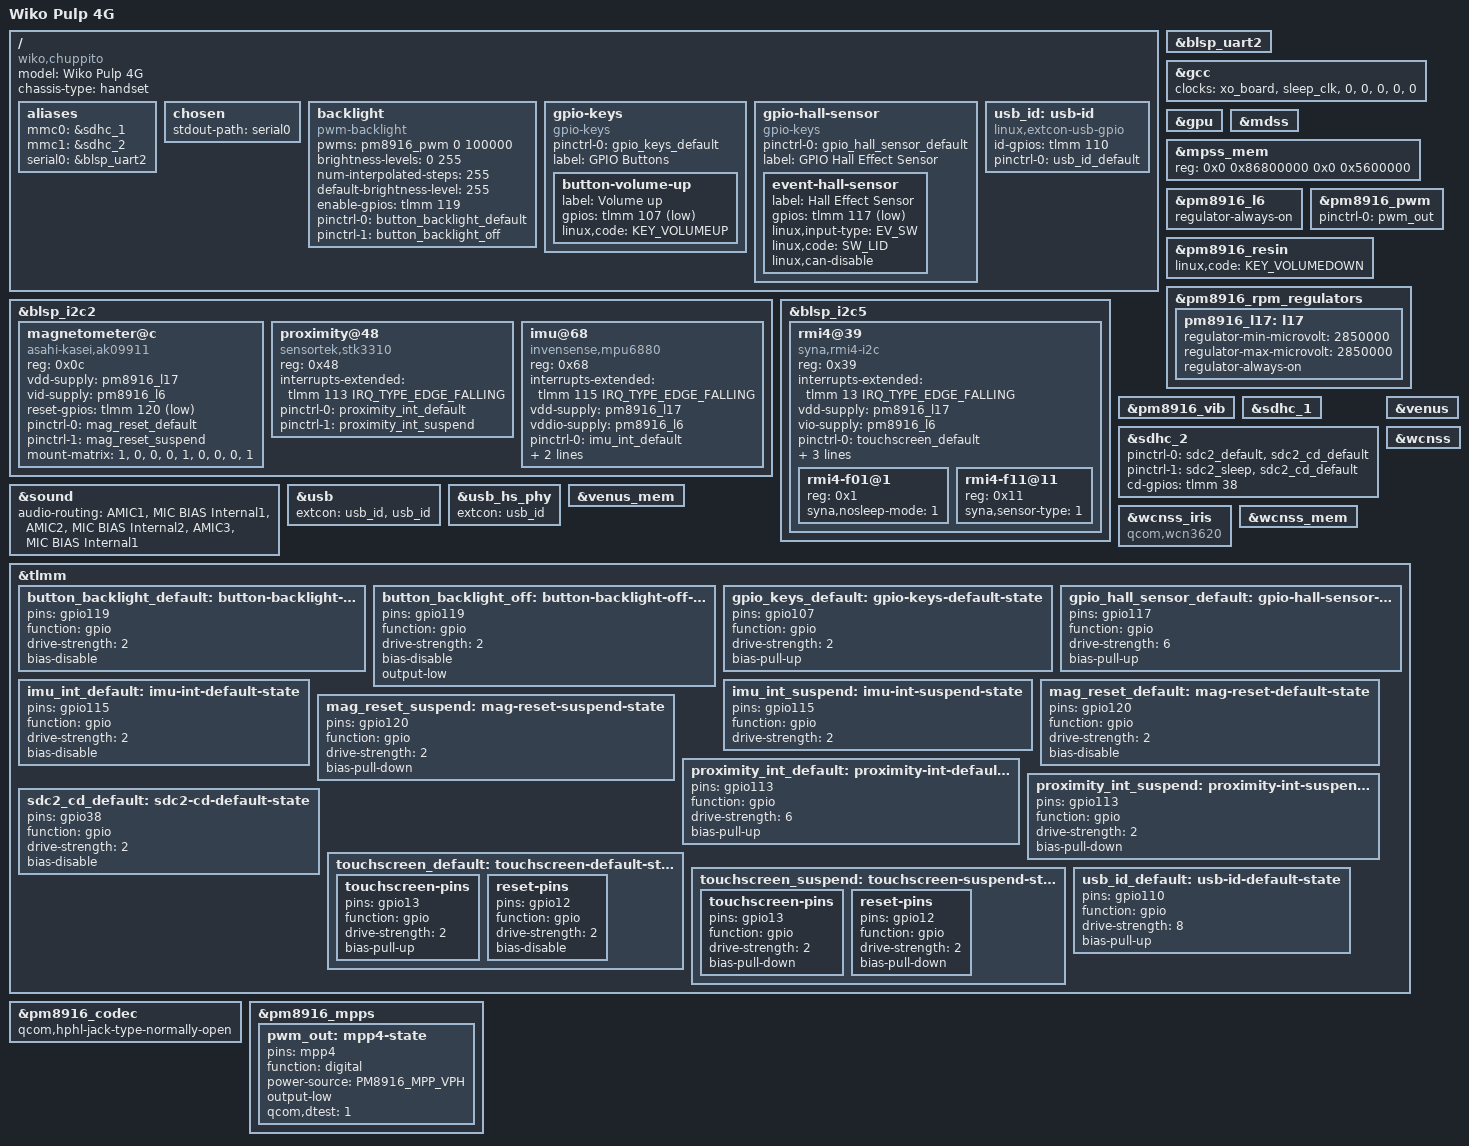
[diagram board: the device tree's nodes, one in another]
// SPDX-License-Identifier: GPL-2.0-only

/dts-v1/;

#include "msm8916-pm8916.dtsi"
#include "msm8916-modem-qdsp6.dtsi"

#include <dt-bindings/gpio/gpio.h>
#include <dt-bindings/input/input.h>
#include <dt-bindings/pinctrl/qcom,pmic-mpp.h>

/ {
	model = "Wiko Pulp 4G";
	compatible = "wiko,chuppito", "qcom,msm8916";
	chassis-type = "handset";

	aliases {
		mmc0 = &sdhc_1; /* eMMC */
		mmc1 = &sdhc_2; /* SD card */
		serial0 = &blsp_uart2;
	};

	chosen {
		stdout-path = "serial0";
	};
	backlight: backlight {
		compatible = "pwm-backlight";
		pwms = <&pm8916_pwm 0 100000>;
		brightness-levels = <0 255>;
		num-interpolated-steps = <255>;
		default-brightness-level = <255>;
		enable-gpios = <&tlmm 119 GPIO_ACTIVE_HIGH>;
		pinctrl-0 = <&button_backlight_default>;
		pinctrl-1 = <&button_backlight_off>;
		pinctrl-names = "default", "off";
	};

	gpio-keys {
		compatible = "gpio-keys";
		pinctrl-0 = <&gpio_keys_default>;
		pinctrl-names = "default";
		label = "GPIO Buttons";

		button-volume-up {
			label = "Volume up";
			gpios = <&tlmm 107 GPIO_ACTIVE_LOW>;
			linux,code = <KEY_VOLUMEUP>;
		};
	};

	gpio-hall-sensor {
		compatible = "gpio-keys";
		pinctrl-0 = <&gpio_hall_sensor_default>;
		pinctrl-names = "default";
		label = "GPIO Hall Effect Sensor";

		event-hall-sensor {
			label = "Hall Effect Sensor";
			gpios = <&tlmm 117 GPIO_ACTIVE_LOW>;
			linux,input-type = <EV_SW>;
			linux,code = <SW_LID>;
			linux,can-disable;
		};
	};

	usb_id: usb-id {
		compatible = "linux,extcon-usb-gpio";
		id-gpios = <&tlmm 110 GPIO_ACTIVE_HIGH>;
		pinctrl-0 = <&usb_id_default>;
		pinctrl-names = "default";
	};
};

&blsp_uart2 {
	status = "okay";
};

&blsp_i2c2 {
	status = "okay";

	magnetometer@c {
		compatible = "asahi-kasei,ak09911";
		reg = <0x0c>;
		vdd-supply = <&pm8916_l17>;
		vid-supply = <&pm8916_l6>;
		reset-gpios = <&tlmm 120 GPIO_ACTIVE_LOW>;
		pinctrl-0 = <&mag_reset_default>;
		pinctrl-1 = <&mag_reset_suspend>;
		pinctrl-names = "default", "suspend";
		mount-matrix = "1",  "0", "0",
			       "0", "1", "0",
			       "0",  "0", "1";
	};

	proximity@48 {
		// downstream devicetree only specifies "stk,stk3x1x"
		compatible = "sensortek,stk3310";
		reg = <0x48>;
		interrupts-extended = <&tlmm 113 IRQ_TYPE_EDGE_FALLING>;
		pinctrl-0 = <&proximity_int_default>;
		pinctrl-1 = <&proximity_int_suspend>;
		pinctrl-names = "default", "suspend";
	};

	imu@68 {
		compatible = "invensense,mpu6880";
		reg = <0x68>;
		interrupts-extended = <&tlmm 115 IRQ_TYPE_EDGE_FALLING>;
		vdd-supply = <&pm8916_l17>;
		vddio-supply = <&pm8916_l6>;
		pinctrl-0 = <&imu_int_default>;
		pinctrl-1 = <&imu_int_suspend>;
		pinctrl-names = "default", "suspend";
		mount-matrix = "0",  "-1", "0",
			       "-1", "0", "0",
			       "0",  "0", "-1";
	};
};

&blsp_i2c5 {
	status = "okay";

	rmi4@39 {
		compatible = "syna,rmi4-i2c";
		reg = <0x39>;
		interrupts-extended = <&tlmm 13 IRQ_TYPE_EDGE_FALLING>;
		vdd-supply = <&pm8916_l17>;
		vio-supply = <&pm8916_l6>;
		pinctrl-0 = <&touchscreen_default>;
		pinctrl-1 = <&touchscreen_suspend>;
		pinctrl-names = "default", "suspend";
		#address-cells = <1>;
		#size-cells = <0>;
		syna,startup-delay-ms = <100>;
		syna,reset-delay-ms = <160>;

		rmi4-f01@1 {
			reg = <0x1>;
			syna,nosleep-mode = <1>;
		};

		rmi4-f11@11 {
			reg = <0x11>;
			syna,sensor-type = <1>;
		};
	};
};

// make sure gcc is probed with display disabled.
&gcc {
	clocks = <&xo_board>, <&sleep_clk>, <0>, <0>, <0>, <0>, <0>;
};

&gpu {
	status = "okay";
};

&mdss {
	status = "okay";
};

&mpss_mem {
	reg = <0x0 0x86800000 0x0 0x5600000>;
};

&pm8916_l6 {
	regulator-always-on;
};

&pm8916_pwm {
	pinctrl-0 = <&pwm_out>;
	pinctrl-names = "default";
	status = "okay";
};

&pm8916_resin {
	linux,code = <KEY_VOLUMEDOWN>;
	status = "okay";
};

&pm8916_rpm_regulators {
	pm8916_l17: l17 {
		regulator-min-microvolt = <2850000>;
		regulator-max-microvolt = <2850000>;
		regulator-always-on;
	};
};

&pm8916_vib {
	status = "okay";
};

&sdhc_1 {
	status = "okay";
};

&sdhc_2 {
	pinctrl-0 = <&sdc2_default>, <&sdc2_cd_default>;
	pinctrl-1 = <&sdc2_sleep>, <&sdc2_cd_default>;
	pinctrl-names = "default", "sleep";
	cd-gpios = <&tlmm 38 GPIO_ACTIVE_HIGH>;
	status = "okay";
};

&sound {
	audio-routing =
		"AMIC1", "MIC BIAS Internal1",
		"AMIC2", "MIC BIAS Internal2",
		"AMIC3", "MIC BIAS Internal1";
};

&usb {
	extcon = <&usb_id>, <&usb_id>;
	status = "okay";
};

&usb_hs_phy {
	extcon = <&usb_id>;
};

&venus {
	status = "okay";
};

&venus_mem {
	status = "okay";
};

&wcnss {
	status = "okay";
};

&wcnss_iris {
	compatible = "qcom,wcn3620";
};

&wcnss_mem {
	status = "okay";
};

&tlmm {
	button_backlight_default: button-backlight-default-state {
		pins = "gpio119";
		function = "gpio";
		drive-strength = <2>;
		bias-disable;
	};

	button_backlight_off: button-backlight-off-state {
	     pins = "gpio119";
	     function = "gpio";
	     drive-strength = <2>;
	     bias-disable;
	     output-low;
	};

	gpio_keys_default: gpio-keys-default-state {
		pins = "gpio107";
		function = "gpio";
		drive-strength = <2>;
		bias-pull-up;
	};

	gpio_hall_sensor_default: gpio-hall-sensor-default-state {
		pins = "gpio117";
		function = "gpio";
		drive-strength = <6>;
		bias-pull-up;
	};

	imu_int_default: imu-int-default-state {
		pins = "gpio115";
		function = "gpio";
		drive-strength = <2>;
		bias-disable;
	};

	imu_int_suspend: imu-int-suspend-state {
		pins = "gpio115";
		function = "gpio";
		drive-strength = <2>;
	};

	mag_reset_default: mag-reset-default-state {
		pins = "gpio120";
		function = "gpio";
		drive-strength = <2>;
		bias-disable;
	};

	mag_reset_suspend: mag-reset-suspend-state {
		pins = "gpio120";
		function = "gpio";
		drive-strength = <2>;
		bias-pull-down;
	};

	proximity_int_default: proximity-int-default-state {
		pins = "gpio113";
		function = "gpio";
		drive-strength = <6>;
		bias-pull-up;
	};

	proximity_int_suspend: proximity-int-suspend-state {
		pins = "gpio113";
		function = "gpio";
		drive-strength = <2>;
		bias-pull-down;
	};

	sdc2_cd_default: sdc2-cd-default-state {
		pins = "gpio38";
		function = "gpio";
		drive-strength = <2>;
		bias-disable;
	};

	touchscreen_default: touchscreen-default-state {
		touchscreen-pins {
			pins = "gpio13";
			function = "gpio";
			drive-strength = <2>;
			bias-pull-up;
		};

		reset-pins {
			pins = "gpio12";
			function = "gpio";
			drive-strength = <2>;
			bias-disable;
		};
	};

	touchscreen_suspend: touchscreen-suspend-state {
		touchscreen-pins {
			pins = "gpio13";
			function = "gpio";
			drive-strength = <2>;
			bias-pull-down;
		};

		reset-pins {
			pins = "gpio12";
			function = "gpio";
			drive-strength = <2>;
			bias-pull-down;
		};
	};

	usb_id_default: usb-id-default-state {
		pins = "gpio110";
		function = "gpio";
		drive-strength = <8>;
		bias-pull-up;
	};
};

&pm8916_codec {
	qcom,hphl-jack-type-normally-open;
};

&pm8916_mpps {
	pwm_out: mpp4-state {
		pins = "mpp4";
		function = "digital";
		power-source = <PM8916_MPP_VPH>;
		output-low;
		qcom,dtest = <1>;
	};
};
